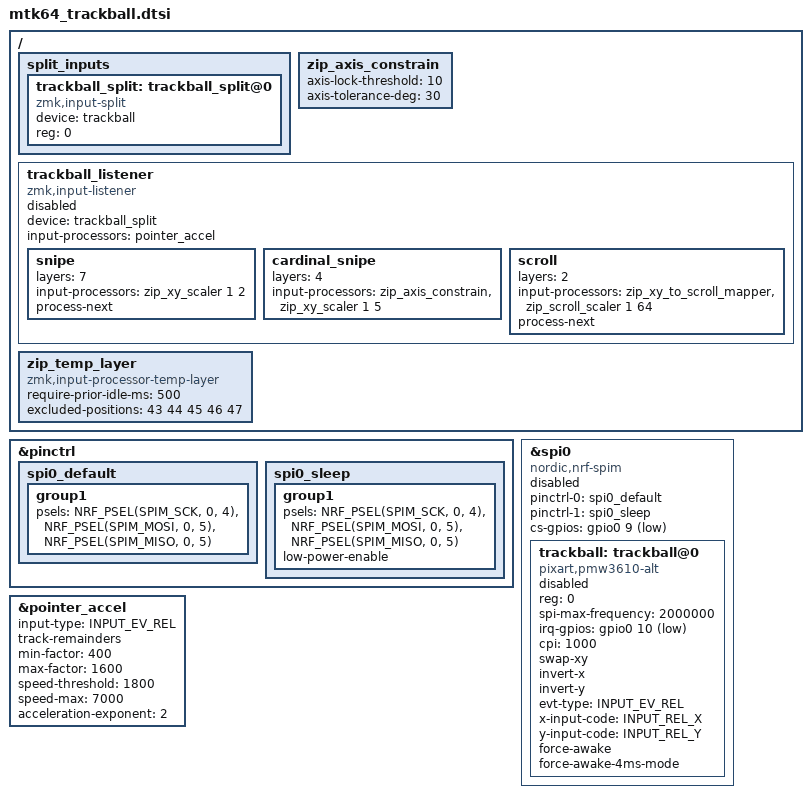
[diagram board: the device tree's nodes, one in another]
#include <zephyr/dt-bindings/input/input-event-codes.h>
#include <input/processors.dtsi>
#include <axis-constrain.dtsi>
#include <behaviors/input_gestures_accel.dtsi>

&pinctrl {
    spi0_default: spi0_default {
        group1 {
            psels = <NRF_PSEL(SPIM_SCK, 0, 4)>,
                <NRF_PSEL(SPIM_MOSI, 0, 5)>,
                <NRF_PSEL(SPIM_MISO, 0, 5)>;
        };
    };

    spi0_sleep: spi0_sleep {
        group1 {
            psels = <NRF_PSEL(SPIM_SCK, 0, 4)>,
                <NRF_PSEL(SPIM_MOSI, 0, 5)>,
                <NRF_PSEL(SPIM_MISO, 0, 5)>;
            low-power-enable;
        };
    };
};

&spi0 {
    status = "disabled";
    compatible = "nordic,nrf-spim";
    pinctrl-0 = <&spi0_default>;
    pinctrl-1 = <&spi0_sleep>;
    pinctrl-names = "default", "sleep";
    cs-gpios = <&gpio0 9 GPIO_ACTIVE_LOW>;

    trackball: trackball@0 {
        status = "disabled";
        compatible = "pixart,pmw3610-alt";
        reg = <0>;
        spi-max-frequency = <2000000>;
        irq-gpios = <&gpio0 10 (GPIO_ACTIVE_LOW | GPIO_PULL_UP)>;
        cpi = <1000>;
        swap-xy;
        invert-x;
        invert-y;
        evt-type = <INPUT_EV_REL>;
        x-input-code = <INPUT_REL_X>;
        y-input-code = <INPUT_REL_Y>;

        force-awake;
        /* keep the sensor awake while ZMK activity state is ACTIVE,
           fallback to normal downshift mode after ZMK goes into IDLE / SLEEP mode.
           thus, the sensor would be a `wakeup-source` */

        force-awake-4ms-mode;
        /* while force-awake is acitvated, enable this mode to force sampling per 
           4ms, where the default sampling rate is 8ms. */
        /* NOTE: apply this mode if you need 250Hz with direct USB connection. */

    };
};

&pointer_accel {
    input-type = <INPUT_EV_REL>;  // For relative input devices
    track-remainders;             // Accumulate fractional movements
    min-factor = <400>;           // 0.4x at very slow speeds
    max-factor = <1600>;          // 1.6x at fast speeds
    speed-threshold = <1800>;     // 1800 counts/sec for 1x
    speed-max = <7000>;           // 7000 counts/sec for max accel
    acceleration-exponent = <2>;  // Quadratic acceleration curve
};

/ {
    split_inputs {
        #address-cells = <1>;
        #size-cells = <0>;

        trackball_split: trackball_split@0 {
            device = <&trackball>;
            compatible = "zmk,input-split";
            reg = <0>;
        };
    };

    zip_axis_constrain: zip_axis_constrain {
        axis-lock-threshold = <10>;
        /* release-after-ms = <150>; */
        axis-tolerance-deg = <30>;
    };

    trackball_listener: trackball_listener {
        compatible = "zmk,input-listener";
        status = "disabled";
        device = <&trackball_split>;

        input-processors = <&pointer_accel>;

        snipe {
        layers = <7>;
        input-processors = <&zip_xy_scaler 1 2>;
        process-next;
        };

        cardinal_snipe {
        layers = <4>;
        input-processors = <&zip_axis_constrain>, <&zip_xy_scaler 1 5>;
        };

        scroll {
        layers = <2>;
        input-processors = <&zip_xy_to_scroll_mapper>, <&zip_scroll_scaler 1 64>;
        process-next;
        };

        /* automouse */
        /* input-processors = <&zip_temp_layer 6 5000>; */

    };

    zip_temp_layer: zip_temp_layer {
        compatible = "zmk,input-processor-temp-layer";
        #input-processor-cells = <2>;
        require-prior-idle-ms = <500>;
        excluded-positions = <
            43  // ] 
            44  // N
            45  // M
            46  // <
            47  // >
        >; 
    };

};

